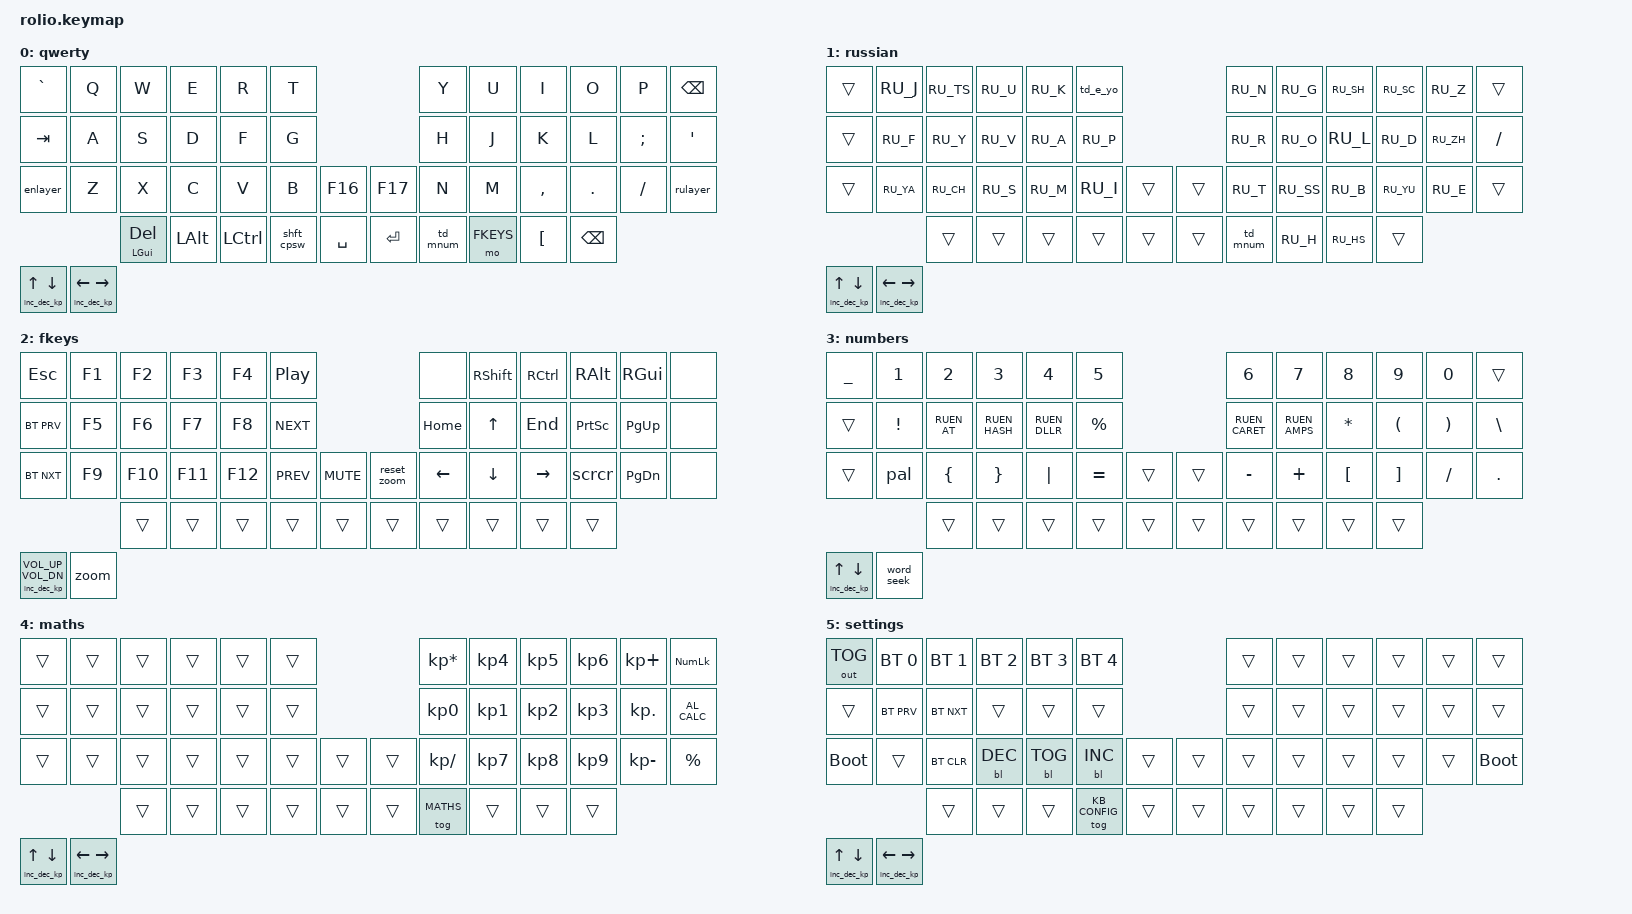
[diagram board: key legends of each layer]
/*
 * Copyright (c) 2020 The ZMK Contributors
 *
 * SPDX-License-Identifier: MIT
 */

#include "zmk-helpers/helper.h"
#include "zmk-helpers/key-labels/rolio46.h"
#include "behaviors.dtsi"
#include "dt-bindings/zmk/backlight.h"
#include "dt-bindings/zmk/bt.h"
#include "dt-bindings/zmk/keys.h"
#include "dt-bindings/zmk/outputs.h"
#include "behaviors/ruen.dtsi"
#include "zmk/ruen_win.h"
#include "locale/keys_ru_short.h"
#include "custom-behaviors.dtsi"
#include "custom-macros.dtsi"
#include "combos.dtsi"
#include "layers.dtsi"

#define NONE &none
#define TRNS &trans

&sk {
    release-after-ms = <2000>;
    lazy;
};

/* Keymap */

ZMK_LAYER(qwerty,
//╭──────────────┬──────────────┬──────────────┬──────────────┬──────────────┬──────────────╮                              ╭──────────────┬──────────────┬──────────────┬──────────────┬──────────────┬──────────────╮
    &kp GRAVE      &kp Q          &kp W          &kp E          &kp R          &kp T                                         &kp Y          &kp U          &kp I          &kp O          &kp P          &kp BSPC
//├──────────────┼──────────────┼──────────────┼──────────────┼──────────────┼──────────────┤                              ├──────────────┼──────────────┼──────────────┼──────────────┼──────────────┼──────────────┤
    &kp TAB        &kp A          &kp S          &kp D          &kp F          &kp G                                         &kp H          &kp J          &kp K          &kp L          &kp SEMI       &kp SQT
//├──────────────┼──────────────┼──────────────┼──────────────┼──────────────┼──────────────┼──────────────╮╭──────────────┼──────────────┼──────────────┼──────────────┼──────────────┼──────────────┼──────────────┤
    &enlayer       &kp Z          &kp X          &kp C          &kp V          &kp B          &kp F16         &kp F17        &kp N          &kp M          &kp COMMA      &kp DOT        &kp FSLH       &rulayer
//╰──────────────┼──────────────┴──────────────┼──────────────┼──────────────┼──────────────┼──────────────┤├──────────────┼──────────────┼──────────────┴──────────────┴──────────────┴──────────────┴──────────────╯
                                  &mt LGUI DEL   &kp LALT       &kp LCTL       &shft_cpsw     &kp SPACE       &kp RET        &td_mnum       &mo FKEYS      &kp LBKT       &kp BSPC,
//                              ╰──────────────┴──────────────┴──────────────┴──────────────┴──────────────╯╰──────────────┴──────────────┴──────────────┴──────────────┴──────────────╯
&inc_dec_kp UP DOWN &inc_dec_kp LEFT RIGHT)

ZMK_LAYER(russian,
//╭──────────────┬──────────────┬──────────────┬──────────────┬──────────────┬──────────────╮                              ╭──────────────┬──────────────┬──────────────┬──────────────┬──────────────┬──────────────╮
    TRNS           &kp RU_J       &kp RU_TS      &kp RU_U       &kp RU_K       &td_e_yo                                      &kp RU_N       &kp RU_G       &kp RU_SH      &kp RU_SC      &kp RU_Z       TRNS
//├──────────────┼──────────────┼──────────────┼──────────────┼──────────────┼──────────────┤                              ├──────────────┼──────────────┼──────────────┼──────────────┼──────────────┼──────────────┤
    TRNS           &kp RU_F       &kp RU_Y       &kp RU_V       &kp RU_A       &kp RU_P                                      &kp RU_R       &kp RU_O       &kp RU_L       &kp RU_D       &kp RU_ZH      &kp FSLH
//├──────────────┼──────────────┼──────────────┼──────────────┼──────────────┼──────────────┼──────────────╮╭──────────────┼──────────────┼──────────────┼──────────────┼──────────────┼──────────────┼──────────────┤
    TRNS           &kp RU_YA      &kp RU_CH      &kp RU_S       &kp RU_M       &kp RU_I       TRNS            TRNS           &kp RU_T       &kp RU_SS      &kp RU_B       &kp RU_YU      &kp RU_E       TRNS
//╰──────────────┼──────────────┴──────────────┼──────────────┼──────────────┼──────────────┼──────────────┤├──────────────┼──────────────┼──────────────┴──────────────┴──────────────┴──────────────┴──────────────╯
                                  TRNS           TRNS           TRNS           TRNS           TRNS            TRNS           &td_mnum       &kp RU_H       &kp RU_HS      TRNS,
//                              ╰──────────────┴──────────────┴──────────────┴──────────────┴──────────────╯╰──────────────┴──────────────┴──────────────┴──────────────┴──────────────╯
&inc_dec_kp UP DOWN &inc_dec_kp LEFT RIGHT)

ZMK_LAYER(fkeys,
//╭──────────────┬──────────────┬──────────────┬──────────────┬──────────────┬──────────────╮                              ╭──────────────┬──────────────┬──────────────┬──────────────┬──────────────┬──────────────╮
    &kp ESCAPE     &kp F1         &kp F2         &kp F3         &kp F4         &kp C_PP                                      NONE           &kp RSHIFT     &kp RCTRL      &kp RALT       &kp RGUI       NONE
//├──────────────┼──────────────┼──────────────┼──────────────┼──────────────┼──────────────┤                              ├──────────────┼──────────────┼──────────────┼──────────────┼──────────────┼──────────────┤
    &bt BT_PRV     &kp F5         &kp F6         &kp F7         &kp F8         &kp C_NEXT                                    &kp HOME       &kp UP         &kp END        &kp PSCRN      &kp PG_UP      NONE
//├──────────────┼──────────────┼──────────────┼──────────────┼──────────────┼──────────────┼──────────────╮╭──────────────┼──────────────┼──────────────┼──────────────┼──────────────┼──────────────┼──────────────┤
    &bt BT_NXT     &kp F9         &kp F10        &kp F11        &kp F12        &kp C_PREV     &kp C_MUTE      &reset_zoom    &kp LEFT       &kp DOWN       &kp RIGHT      &scrcr         &kp PG_DN      NONE
//╰──────────────┼──────────────┴──────────────┼──────────────┼──────────────┼──────────────┼──────────────┤├──────────────┼──────────────┼──────────────┴──────────────┴──────────────┴──────────────┴──────────────╯
                                  TRNS           TRNS           TRNS           TRNS           TRNS            TRNS           TRNS           TRNS           TRNS           TRNS,
//                              ╰──────────────┴──────────────┴──────────────┴──────────────┴──────────────╯╰──────────────┴──────────────┴──────────────┴──────────────┴──────────────╯
&inc_dec_kp C_VOL_UP C_VOL_DN &zoom
)

ZMK_LAYER(numbers,
//╭──────────────────┬──────────────────┬──────────────────┬──────────────────┬──────────────────┬──────────────────╮                                      ╭──────────────────┬──────────────────┬──────────────────┬──────────────────┬──────────────────┬──────────────────╮
    &kp UNDER          &kp N1             &kp N2             &kp N3             &kp N4             &kp N5                                                    &kp N6             &kp N7             &kp N8             &kp N9             &kp N0             TRNS
//├──────────────────┼──────────────────┼──────────────────┼──────────────────┼──────────────────┼──────────────────┤                                      ├──────────────────┼──────────────────┼──────────────────┼──────────────────┼──────────────────┼──────────────────┤
    TRNS               &kp EXCL           RUEN_AT            RUEN_HASH          RUEN_DLLR          &kp PRCNT                                                 RUEN_CARET         RUEN_AMPS          &kp STAR           &kp LPAR           &kp RPAR           &kp BSLH
//├──────────────────┼──────────────────┼──────────────────┼──────────────────┼──────────────────┼──────────────────┼──────────────────╮╭──────────────────┼──────────────────┼──────────────────┼──────────────────┼──────────────────┼──────────────────┼──────────────────┤
    TRNS               &pal               &kp LBRC           &kp RBRC           &kp PIPE           &kp EQUAL          TRNS                TRNS               &kp MINUS          &kp PLUS           &kp LBKT           &kp RBKT           &kp FSLH           &kp DOT
//╰──────────────────┼──────────────────┴──────────────────┼──────────────────┼──────────────────┼──────────────────┼──────────────────┤├──────────────────┼──────────────────┼──────────────────┴──────────────────┴──────────────────┴──────────────────┴──────────────────╯
                                          TRNS               TRNS               TRNS               TRNS               TRNS                TRNS               TRNS               TRNS              TRNS               TRNS,
//                                      ╰──────────────────┴──────────────────┴──────────────────┴──────────────────┴──────────────────╯╰──────────────────┴──────────────────┴──────────────────┴──────────────────┴──────────────────╯
&inc_dec_kp UP DOWN &word_seek
)

ZMK_LAYER(maths,
//╭──────────────┬──────────────┬──────────────┬──────────────┬──────────────┬──────────────╮                              ╭───────────────┬──────────────┬──────────────┬──────────────┬──────────────┬──────────────╮
    TRNS           TRNS           TRNS           TRNS           TRNS          TRNS                                           &kp KP_MULTIPLY &kp KP_N4      &kp KP_N5      &kp KP_N6      &kp KP_PLUS    &kp KP_NUM
//├──────────────┼──────────────┼──────────────┼──────────────┼──────────────┼──────────────┤                              ├───────────────┼──────────────┼──────────────┼──────────────┼──────────────┼──────────────┤
    TRNS           TRNS           TRNS           TRNS           TRNS           TRNS                                          &kp KP_N0       &kp KP_N1      &kp KP_N2      &kp KP_N3      &kp KP_DOT     &kp C_AL_CALC
//├──────────────┼──────────────┼──────────────┼──────────────┼──────────────┼──────────────┼──────────────╮╭──────────────┼───────────────┼──────────────┼──────────────┼──────────────┼──────────────┼──────────────┤
    TRNS           TRNS           TRNS           TRNS           TRNS           TRNS           TRNS           TRNS            &kp KP_DIVIDE   &kp KP_N7      &kp KP_N8      &kp KP_N9      &kp KP_MINUS   &kp PRCNT
//╰──────────────┼──────────────┴──────────────┼──────────────┼──────────────┼──────────────┼──────────────┤├──────────────┼───────────────┼──────────────┴──────────────┴──────────────┴──────────────┴──────────────╯
                                  TRNS           TRNS           TRNS           TRNS           TRNS            TRNS           &tog MATHS      TRNS           TRNS            TRNS,
//                              ╰──────────────┴──────────────┴──────────────┴──────────────┴──────────────╯╰──────────────┴───────────────┴──────────────┴──────────────┴──────────────╯
&inc_dec_kp UP DOWN &inc_dec_kp LEFT RIGHT
)

ZMK_LAYER(settings,
//╭──────────────┬──────────────┬──────────────┬──────────────┬──────────────┬──────────────╮                               ╭──────────────┬──────────────┬──────────────┬──────────────┬──────────────┬──────────────╮
    &out OUT_TOG   &bt BT_SEL 0   &bt BT_SEL 1   &bt BT_SEL 2   &bt BT_SEL 3   &bt BT_SEL 4                                   TRNS           TRNS           TRNS           TRNS           TRNS           TRNS
//├──────────────┼──────────────┼──────────────┼──────────────┼──────────────┼──────────────┤                               ├──────────────┼──────────────┼──────────────┼──────────────┼──────────────┼──────────────┤
    TRNS           &bt BT_PRV     &bt BT_NXT     TRNS           TRNS           TRNS                                           TRNS           TRNS           TRNS           TRNS           TRNS           TRNS
//├──────────────┼──────────────┼──────────────┼──────────────┼──────────────┼──────────────┼──────────────╮ ╭──────────────┼──────────────┼──────────────┼──────────────┼──────────────┼──────────────┼──────────────┤
    &bootloader    TRNS           &bt BT_CLR     &bl BL_DEC     &bl BL_TOG     &bl BL_INC     TRNS             TRNS           TRNS           TRNS           TRNS           TRNS           TRNS           &bootloader
//╰──────────────┼──────────────┴──────────────┼──────────────┼──────────────┼──────────────┼──────────────┤ ├──────────────┼──────────────┼──────────────┴──────────────┴──────────────┴──────────────┴──────────────╯
                                  TRNS           TRNS           TRNS           &tog KB_CONFIG TRNS             TRNS           TRNS           TRNS           TRNS           TRNS,
//                              ╰──────────────┴──────────────┴──────────────┴──────────────┴──────────────╯ ╰──────────────┴──────────────┴──────────────┴──────────────┴──────────────╯
&inc_dec_kp UP DOWN &inc_dec_kp LEFT RIGHT
)

/ {

    behaviors {
       
        // Toggle Numbers layer

        td_mnum: tap_dance_math_numbers {
            compatible = "zmk,behavior-tap-dance";
            label = "TAP_DANCE_MATS_NUMBERS";
            #binding-cells = <0>;
            tapping-term-ms = <300>;
            bindings = <&mo NUMBERS>, <&tog MATHS>, <&tog NUMBERS>;
        };

        td_mnum_rus: tap_dance_math_numbers_rus {
            compatible = "zmk,behavior-tap-dance";
            label = "TAP_DANCE_MATS_NUMBERS_RUS";
            #binding-cells = <0>;
            tapping-term-ms = <300>;
            bindings = <&m_numbers_rus>, <&tog MATHS>, <&tog NUMBERS>;
        };

        // Word Seek

        word_seek: word_seek {
            compatible = "zmk,behavior-sensor-rotate";
            label = "WORD_SEEK";
            #sensor-binding-cells = <0>;
            tap-ms = <20>;
            bindings = <&prev_word>, <&next_word>;
        };

        //OS Zoom

        zoom: zoom {
            compatible = "zmk,behavior-sensor-rotate";
            label = "WINDOWS_ZOOM";
            #sensor-binding-cells = <0>;
            bindings = <&zoom_in>, <&zoom_out>;
        };

        td_e_yo: td_e_yo {
            compatible = "zmk,behavior-tap-dance";
            label = "TD_E_YO";
            #binding-cells = <0>;
            tapping-term-ms = <200>;
            bindings = <&kp RU_JE>, <&kp RU_JO>;
        };

        td_mzn_tzn: td_mzn_tzn {
            compatible = "zmk,behavior-tap-dance";
            label = "TD_MZN_TZN";
            #binding-cells = <0>;
            tapping-term-ms = <175>;
            bindings = <&kp M>, <&kp RBKT>;
        };

        ht_hrm_left: ht_hrm_left {
            compatible = "zmk,behavior-hold-tap";
            label = "HT_HRM_LEFT";
            bindings = <&kp>, <&kp>;

            #binding-cells = <2>;
            tapping-term-ms = <300>;
            flavor = "balanced";
            quick-tap-ms = <175>;
            require-prior-idle-ms = <150>;
            hold-trigger-key-positions = <37 23 11 10 22 36 35 21 9 8 20 34 33 19 7 6 18 32 31 43 44 45 46 47>;
        };

        ht_hrm_right: ht_hrm_right {
            compatible = "zmk,behavior-hold-tap";
            label = "HT_HRM_RIGHT";
            bindings = <&kp>, <&kp>;

            #binding-cells = <2>;
            tapping-term-ms = <300>;
            flavor = "balanced";
            quick-tap-ms = <175>;
            require-prior-idle-ms = <150>;
            hold-trigger-key-positions = <42 30 29 41 17 5 4 16 28 40 39 27 15 3 2 14 26 38 25 13 1 0 12 24>;
        };

        shft_cpsw: td_shift_capsw {
            compatible = "zmk,behavior-tap-dance";
            label = "TAP_DANCE_LSHIFT_CAPSWORD";
            #binding-cells = <0>;
            tapping-term-ms = <200>;
            bindings = <&kp LSHFT>, <&caps_word>;
        };

        ruen_one_key: ruen_one_key {
            compatible = "zmk,behavior-ruen-one-key";
            #binding-cells = <2>;
            to_en = <0x0307001e>;
            to_ru = <0x0307001f>;
        };

        HOLD_COMBO_BEHAVIOR(htnumbers_rus, <&m_numbers_rus>) // macro_numbers_rus on hold and kp on tap
    };

    macros {

        rulang: rulang {
            label = "rulang";
            compatible = "zmk,behavior-macro";
            #binding-cells = <0>;
            bindings = 
                <&macro_press &kp LCTRL>,
                <&macro_press &kp LSHIFT>,
                <&macro_tap &kp N2>,
                <&macro_release &kp LCTRL>,
                <&macro_release &kp LSHIFT>
            ;
        };

        enlang: enlang {
            label = "enlang";
            compatible = "zmk,behavior-macro";
            #binding-cells = <0>;
            bindings = 
                <&macro_press &kp LCTRL>,
                <&macro_press &kp LSHIFT>,
                <&macro_tap &kp N1>,
                <&macro_release &kp LCTRL>,
                <&macro_release &kp LSHIFT>
            ;
        };

        rulayer: rulayer {
            label = "rulayer";
            compatible = "zmk,behavior-macro";
            #binding-cells = <0>;
            bindings = 
                <&rulang>,
                <&ruen_set 0>,
                <&macro_tap &to RUS> 
            ;
        };

        enlayer: enlayer {
            label = "enlayer";
            compatible = "zmk,behavior-macro";
            #binding-cells = <0>;
            bindings = 
                <&enlang>,
                <&ruen_set 1>,
                <&macro_tap &to ENG> 
            ;
        };

        unindent: unindent {
            label = "UNINDENT";
            compatible = "zmk,behavior-macro";
            #binding-cells = <0>;
            bindings =
                <&macro_press>,
                <&kp LSHIFT>,
                <&macro_tap>,
                <&kp TAB>,
                <&macro_release>,
                <&kp LSHIFT>;
        };

        lstart: lstart {
            label = "Line_Start";
            compatible = "zmk,behavior-macro";
            #binding-cells = <0>;
            bindings =
                <&macro_press>,
                <&kp LGUI>,
                <&macro_tap>,
                <&kp LEFT>,
                <&macro_release>,
                <&kp LGUI>;
        };

        lend: lend {
            label = "Line_End";
            compatible = "zmk,behavior-macro";
            #binding-cells = <0>;
            bindings =
                <&macro_press>,
                <&kp LGUI>,
                <&macro_tap>,
                <&kp RIGHT>,
                <&macro_release>,
                <&kp LGUI>;
        };

        scrsh: scrsh {
            label = "Screenshot";
            compatible = "zmk,behavior-macro";
            #binding-cells = <0>;
            bindings =
                <&macro_press>,
                <&kp LGUI>,
                <&macro_press>,
                <&kp LSHIFT>,
                <&macro_tap>,
                <&kp N3>,
                <&macro_release>,
                <&kp LSHFT>,
                <&macro_release>,
                <&kp LGUI>;
        };

        scrcr: scrcr {
            label = "Windows_Screen_Crop";
            compatible = "zmk,behavior-macro";
            #binding-cells = <0>;
            bindings =
                <&macro_press>,
                <&kp LGUI>,
                <&macro_press>,
                <&kp LSHIFT>,
                <&macro_tap>,
                <&kp S>,
                <&macro_release>,
                <&kp LSHFT>,
                <&macro_release>,
                <&kp LGUI>;
        };

        pal: pal {
            label = "Pallette";
            compatible = "zmk,behavior-macro";
            #binding-cells = <0>;
            bindings =
                <&macro_press>,
                <&kp LGUI>,
                <&macro_tap>,
                <&kp DOT>,
                <&macro_release>,
                <&kp LGUI>;
        };

        // Word seek macros

        prev_word: prev_word {
            label = "PREV_WORD";
            compatible = "zmk,behavior-macro";
            wait-ms = <2>;
            tap-ms = <20>;
            #binding-cells = <0>;
            bindings =
                <&macro_press>,
                <&kp LCTRL>,
                <&macro_tap>,
                <&kp LEFT>,
                <&macro_release>,
                <&kp LCTRL>;
        };

        next_word: next_word {
            label = "NEXT_WORD";
            compatible = "zmk,behavior-macro";
            wait-ms = <2>;
            tap-ms = <20>;
            #binding-cells = <0>;
            bindings =
                <&macro_press>,
                <&kp LCTRL>,
                <&macro_tap>,
                <&kp RIGHT>,
                <&macro_release>,
                <&kp LCTRL>;
        };

        // Zoom macros

        zoom_in: zoom_in {
            label = "WINDOWS_ZOOM_IN";
            compatible = "zmk,behavior-macro";
            #binding-cells = <0>;
            bindings =
                <&macro_press>,
                <&kp LCTRL>,
                <&macro_tap>,
                <&kp EQUAL>,
                <&macro_release>,
                <&kp LCTRL>;
        };

        zoom_out: zoom_out {
            label = "WINDOWS_ZOOM_OUT";
            compatible = "zmk,behavior-macro";
            #binding-cells = <0>;
            bindings =
                <&macro_press>,
                <&kp LCTRL>,
                <&macro_tap>,
                <&kp MINUS>,
                <&macro_release>,
                <&kp LCTRL>;
        };

        reset_zoom: reset_zoom {
            label = "WINDOWS_RESET_ZOOM";
            compatible = "zmk,behavior-macro";
            #binding-cells = <0>;
            bindings =
                <&macro_press>,
                <&kp LCTRL>,
                <&macro_tap>,
                <&kp N0>,
                <&macro_release>,
                <&kp LCTRL>;
        };

        SWITCH_LANG_AND_MO_LAYER_MACRO(numbers_rus, NUMBERS, ENG_NUM, SECOND_NUM)
        SWITCH_LANG_AND_TO_LAYER_MACRO(tom_rus, RUS, SECOND_NUM)
        SWITCH_LANG_AND_TO_LAYER_MACRO(tom_eng, ENG, ENG_NUM)
        SWITCH_LANG_AND_KP_MACRO(kp_number, HASH, SECOND_NUM, ENG_NUM)

    };
 
};
